# RX64M_MPU_Pilot register map
File version: 1.0
RX64M_MPU_Pilot peripheral registers generated from iodefine.h (pilot).
Registers are 32-bit, read-write, reset 0x0 unless marked. A register's access mark holds for its fields unless they carry their own. Offsets are from the block's base; lines under a group give offsets from that group; [hi:lo] are bit positions; {n}, {i} and the like mark numbered series; 'fields as' and 'values as' point back to an identical list; <NAME> marks a mode.

## Memory map
0x00086400 MPU size 0x130

## MPU
Base 0x00086400
{0x0+8i} RSPAGE{i} (reset mask 0xF) (i=0..7)
  [31:4] RSPN
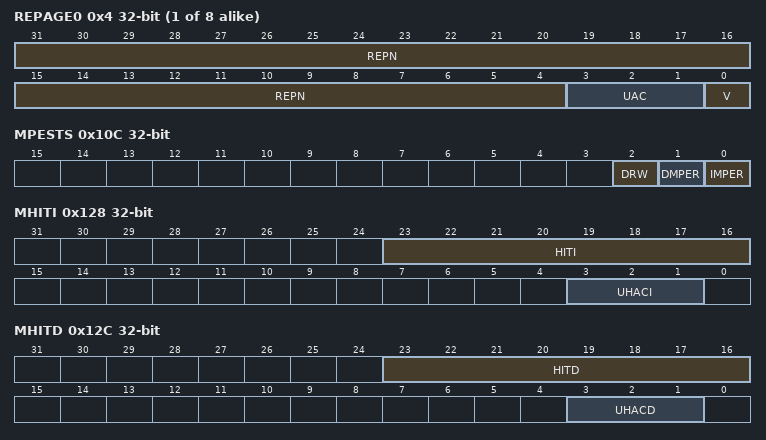
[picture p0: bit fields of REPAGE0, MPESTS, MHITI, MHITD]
{0x4+8i} REPAGE{i} (reset mask 0xF) (i=0..7)
  [31:4] REPN, [3:1] UAC, [0] V
0x100 MPEN
  [0] MPEN
0x104 MPBAC
  [3:1] UBAC
0x108 MPECLR
  [0] CLR
0x10C MPESTS
  [2] DRW, [1] DMPER, [0] IMPER
0x114 MPDEA ro reset not defined
  [31:0] DEA
0x120 MPSA reset not defined
  [31:0] SA
0x124 MPOPS 16-bit
  [0] S
0x126 MPOPI 16-bit
  [0] INV
0x128 MHITI
  [23:16] HITI, [3:1] UHACI
0x12C MHITD
  [23:16] HITD, [3:1] UHACD
